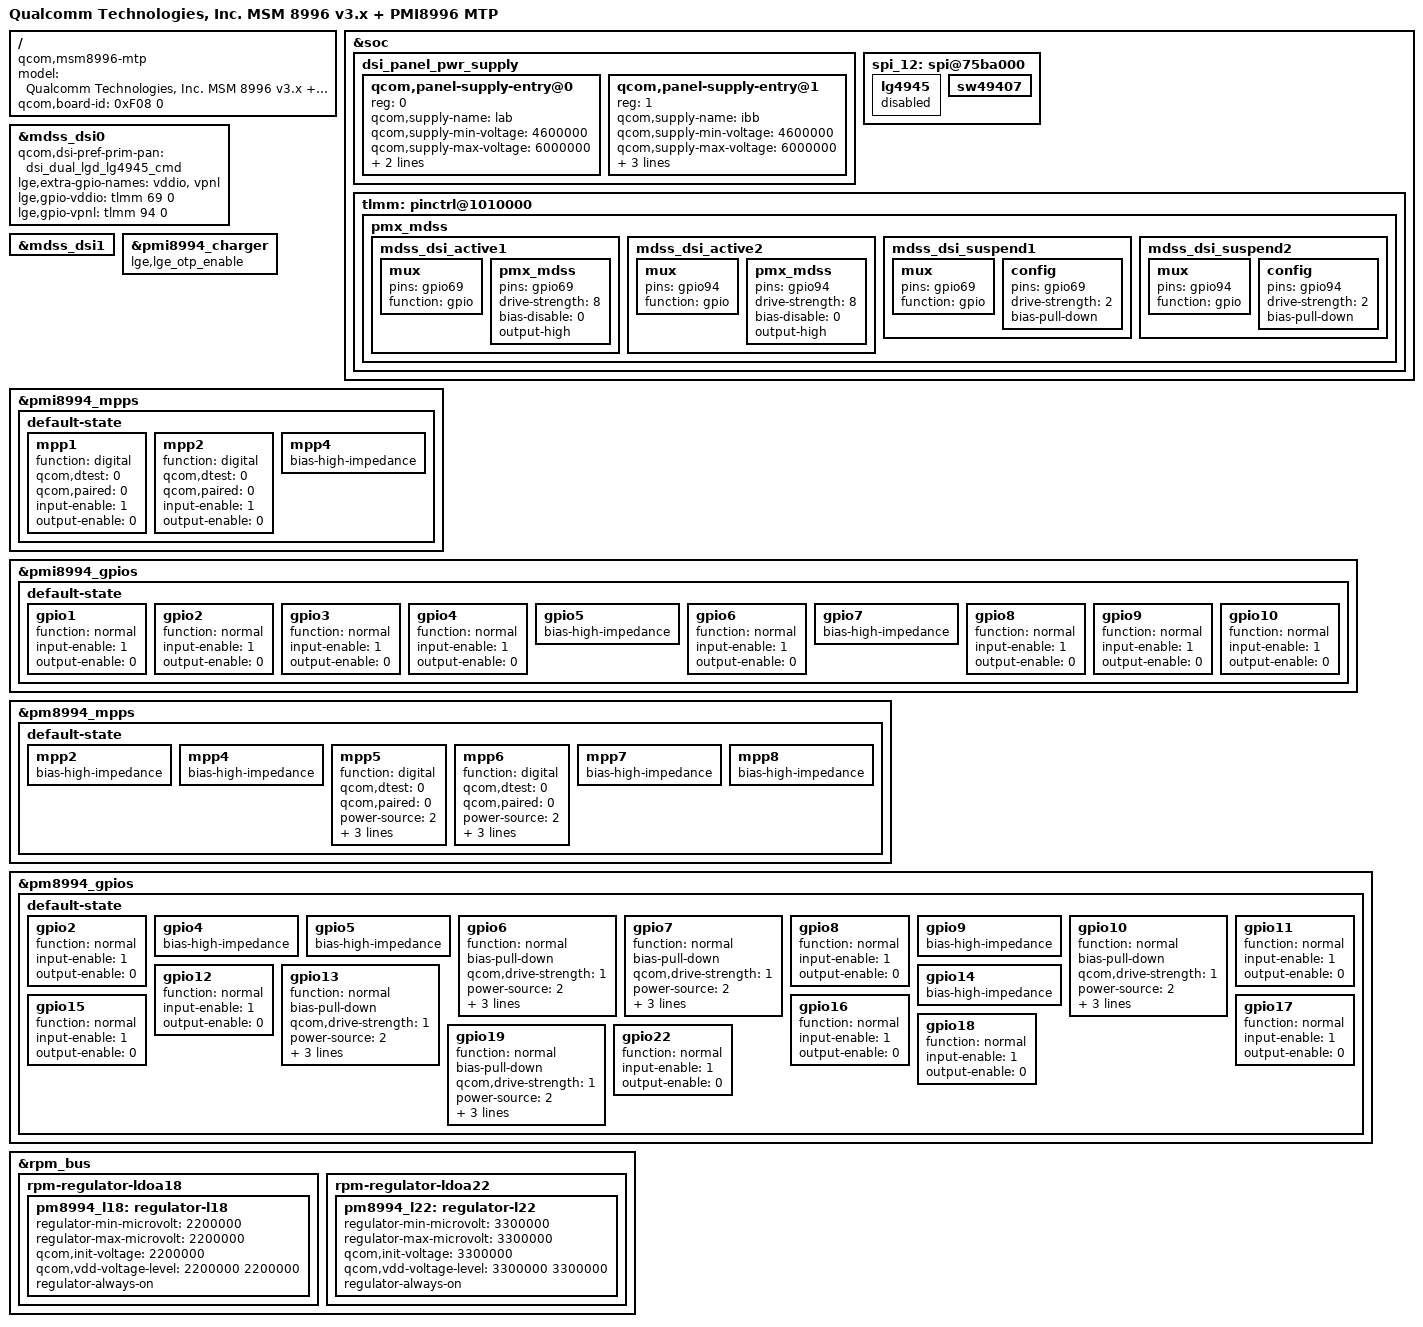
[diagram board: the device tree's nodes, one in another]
/* Copyright (c) 2015, The Linux Foundation. All rights reserved.
 *
 * This program is free software; you can redistribute it and/or modify
 * it under the terms of the GNU General Public License version 2 and
 * only version 2 as published by the Free Software Foundation.
 *
 * This program is distributed in the hope that it will be useful,
 * but WITHOUT ANY WARRANTY; without even the implied warranty of
 * MERCHANTABILITY or FITNESS FOR A PARTICULAR PURPOSE.  See the
 * GNU General Public License for more details.
 */


/dts-v1/;

#include "../../../qcom/msm8996-v3.dtsi"
#include "../../../qcom/msm-pmi8996.dtsi"
#include "../../../qcom/msm8996-mtp.dtsi"
#include "msm8996-elsa_global_com.dtsi"
#include "../common/camera/camera_rev-1.0.dtsi"
#include "../common/sound/sound_rev-1_0.dtsi"

/ {
	model = "Qualcomm Technologies, Inc. MSM 8996 v3.x + PMI8996 MTP";
	compatible = "qcom,msm8996-mtp", "qcom,msm8996", "qcom,mtp";
	qcom,board-id = <0xF08 0>;
};

/* Display Function */
&soc {
	dsi_panel_pwr_supply: dsi_panel_pwr_supply {
		#address-cells = <1>;
		#size-cells = <0>;

		qcom,panel-supply-entry@0 {
			reg = <0>;
			qcom,supply-name = "lab";
			qcom,supply-min-voltage = <4600000>;
			qcom,supply-max-voltage = <6000000>;
			qcom,supply-enable-load = <100000>;
			qcom,supply-disable-load = <100>;
		};

		qcom,panel-supply-entry@1 {
			reg = <1>;
			qcom,supply-name = "ibb";
			qcom,supply-min-voltage = <4600000>;
			qcom,supply-max-voltage = <6000000>;
			qcom,supply-enable-load = <100000>;
			qcom,supply-disable-load = <100>;
			qcom,supply-post-on-sleep = <20>;
		};
	};

	spi_12: spi@75ba000{    /* BLSP-2 QUP6 */
		lg4945 {
			status = "disabled";
		};
		sw49407 {
			status = "ok";
		};
	};
};

&mdss_dsi0 {
	qcom,dsi-pref-prim-pan = <&dsi_dual_lgd_lg4945_cmd>;
	lge,extra-gpio-names = "vddio", "vpnl";

	lge,gpio-vddio = <&tlmm 69 0>;
	lge,gpio-vpnl = <&tlmm 94 0>;
};

&mdss_dsi1 {
	/delete-property/cell-index;
};

/* pinctrl for Display function
 * GPIO69 : LCD_VDD_IO_EN
 * GPIO94 : LCD_VCL_EN
 */
&soc {
	tlmm: pinctrl@1010000 {
		pmx_mdss: pmx_mdss {
			mdss_dsi_active1: mdss_dsi_active1 {
				mux {
					pins = "gpio69";
					function = "gpio";
				};

				pmx_mdss {
					pins = "gpio69";
					drive-strength = <8>; /* 8 mA */
					bias-disable = <0>; /* no pull */
					output-high;
				};
			};
			mdss_dsi_active2: mdss_dsi_active2 {
				mux {
					pins = "gpio94";
					function = "gpio";
				};

				pmx_mdss {
					pins = "gpio94";
					drive-strength = <8>; /* 8 mA */
					bias-disable = <0>; /* no pull */
					output-high;
				};
			};
			mdss_dsi_suspend1: mdss_dsi_suspend1 {
				mux {
					pins = "gpio69";
					function = "gpio";
				};

				config {
					pins = "gpio69";
					drive-strength = <2>; /* 2 mA */
					bias-pull-down; /* pull down */
				};
			};
			mdss_dsi_suspend2: mdss_dsi_suspend2 {
				mux {
					pins = "gpio94";
					function = "gpio";
				};

				config {
					pins = "gpio94";
					drive-strength = <2>; /* 2 mA */
					bias-pull-down; /* pull down */
				};
			};
		};
	};
};

&pmi8994_charger {
    lge,lge_otp_enable;
};

/* set unused and changed assigne gpios on here */
&pmi8994_mpps {
	default-state {
/* Must not define the mpp(mpp 3) on here */
	mpp1 {
			function = "digital";
			qcom,dtest = <0>;
			qcom,paired = <0>;
			input-enable = <1>;
			output-enable = <0>;
			/delete-property/ output-low;
			/delete-property/ output-high;
			/delete-property/ bias-high-impedance;
			status = "okay";
		};

	mpp2 {
			function = "digital";
			qcom,dtest = <0>;
			qcom,paired = <0>;
			input-enable = <1>;
			output-enable = <0>;
			/delete-property/ output-low;
			/delete-property/ output-high;
			/delete-property/ bias-high-impedance;
			status = "okay";
		};

	mpp4 {
			bias-high-impedance;
			status = "okay";
		};
	};
};

&pmi8994_gpios {
	default-state {
	gpio1 {
			function = "normal";
			input-enable = <1>;
			output-enable = <0>;
			/delete-property/ output-low;
			/delete-property/ output-high;
			/delete-property/ bias-high-impedance;
			status = "okay";
		};

	gpio2 {
			function = "normal";
			input-enable = <1>;
			output-enable = <0>;
			/delete-property/ output-low;
			/delete-property/ output-high;
			/delete-property/ bias-high-impedance;
			status = "okay";
		};

	gpio3 {
			function = "normal";
			input-enable = <1>;
			output-enable = <0>;
			/delete-property/ output-low;
			/delete-property/ output-high;
			/delete-property/ bias-high-impedance;
			status = "okay";
		};

	gpio4 {
			function = "normal";
			input-enable = <1>;
			output-enable = <0>;
			/delete-property/ output-low;
			/delete-property/ output-high;
			/delete-property/ bias-high-impedance;
			status = "okay";
		};

	gpio5 {
			bias-high-impedance;
			status = "okay";
		};

	gpio6 {
			function = "normal";
			input-enable = <1>;
			output-enable = <0>;
			/delete-property/ output-low;
			/delete-property/ output-high;
			/delete-property/ bias-high-impedance;
			status = "okay";
		};

	gpio7 {
			bias-high-impedance;
			status = "okay";
		};

	gpio8 {
			function = "normal";
			input-enable = <1>;
			output-enable = <0>;
			/delete-property/ output-low;
			/delete-property/ output-high;
			/delete-property/ bias-high-impedance;
			status = "okay";
		};

	gpio9 {
			function = "normal";
			input-enable = <1>;
			output-enable = <0>;
			/delete-property/ output-low;
			/delete-property/ output-high;
			/delete-property/ bias-high-impedance;
			status = "okay";
		};

	gpio10 {
			function = "normal";
			input-enable = <1>;
			output-enable = <0>;
			/delete-property/ output-low;
			/delete-property/ output-high;
			/delete-property/ bias-high-impedance;
			status = "okay";
		};
	};
};

&pm8994_mpps {
	default-state {
/* Must not define the mpps(mpp 1 and 3) on here */
	mpp2 {
			bias-high-impedance;
			status = "okay";
		};

	mpp4 {
			bias-high-impedance;
			status = "okay";
		};

	mpp5 {
			function = "digital";
			qcom,dtest = <0>;
			qcom,paired = <0>;
			power-source = <2>;
			input-enable = <0>;
			output-enable = <1>;
			/delete-property/ output-low;
			/delete-property/ output-high;
			output-low;
			/delete-property/ bias-high-impedance;
			status = "okay";
		};

	mpp6 {
			function = "digital";
			qcom,dtest = <0>;
			qcom,paired = <0>;
			power-source = <2>;
			input-enable = <0>;
			output-enable = <1>;
			/delete-property/ output-low;
			/delete-property/ output-high;
			output-low;
			/delete-property/ bias-high-impedance;
			status = "okay";
		};

	mpp7 {
			bias-high-impedance;
			status = "okay";
		};

	mpp8 {
			bias-high-impedance;
			status = "okay";
		};
	};
};

&pm8994_gpios {
	default-state {
/* Gpio 1 and 3 is set on relevant usb-type-c */
/* at "kernel\arch\arm64\boot\dts\lge\msm8996-usb-typec-anx7418.dtsi" */
/* Must not define the gpios(gpio 20 and 21) on here */
	gpio2 {
			function = "normal";
			input-enable = <1>;
			output-enable = <0>;
			/delete-property/ output-low;
			/delete-property/ output-high;
			/delete-property/ bias-high-impedance;
			status = "okay";
		};

	gpio4 {
			bias-high-impedance;
			status = "okay";
		};

	gpio5 {
			bias-high-impedance;
			status = "okay";
		};

	gpio6 {
			function = "normal";
			/delete-property/ bias-disable;
			/delete-property/ bias-pull-down;
			/delete-property/ qcom,pull-up-strength;
			bias-pull-down;
			qcom,drive-strength = <1>;
			power-source = <2>;
			input-enable = <0>;
			output-enable = <1>;
			/delete-property/ output-low;
			/delete-property/ output-high;
			output-low;
			/delete-property/ bias-high-impedance;
			status = "okay";
		};

	gpio7 {
			function = "normal";
			/delete-property/ bias-disable;
			/delete-property/ bias-pull-down;
			/delete-property/ qcom,pull-up-strength;
			bias-pull-down;
			qcom,drive-strength = <1>;
			power-source = <2>;
			input-enable = <0>;
			output-enable = <1>;
			/delete-property/ output-low;
			/delete-property/ output-high;
			output-low;
			/delete-property/ bias-high-impedance;
			status = "okay";
		};

	gpio8 {
			function = "normal";
			input-enable = <1>;
			output-enable = <0>;
			/delete-property/ output-low;
			/delete-property/ output-high;
			/delete-property/ bias-high-impedance;
			status = "okay";
		};

	gpio9 {
			bias-high-impedance;
			status = "okay";
		};

	gpio10 {
			function = "normal";
			/delete-property/ bias-disable;
			/delete-property/ bias-pull-down;
			/delete-property/ qcom,pull-up-strength;
			bias-pull-down;
			qcom,drive-strength = <1>;
			power-source = <2>;
			input-enable = <0>;
			output-enable = <1>;
			/delete-property/ output-low;
			/delete-property/ output-high;
			output-low;
			/delete-property/ bias-high-impedance;
			status = "okay";
		};

	gpio11 {
			function = "normal";
			input-enable = <1>;
			output-enable = <0>;
			/delete-property/ output-low;
			/delete-property/ output-high;
			/delete-property/ bias-high-impedance;
			status = "okay";
		};

	gpio12 {
			function = "normal";
			input-enable = <1>;
			output-enable = <0>;
			/delete-property/ output-low;
			/delete-property/ output-high;
			/delete-property/ bias-high-impedance;
			status = "okay";
		};

	gpio13 {
			function = "normal";
			/delete-property/ bias-disable;
			/delete-property/ bias-pull-down;
			/delete-property/ qcom,pull-up-strength;
			bias-pull-down;
			qcom,drive-strength = <1>;
			power-source = <2>;
			input-enable = <0>;
			output-enable = <1>;
			/delete-property/ output-low;
			/delete-property/ output-high;
			output-low;
			/delete-property/ bias-high-impedance;
			status = "okay";
		};

	gpio14 {
			bias-high-impedance;
			status = "okay";
		};

	gpio15 {
			function = "normal";
			input-enable = <1>;
			output-enable = <0>;
			/delete-property/ output-low;
			/delete-property/ output-high;
			/delete-property/ bias-high-impedance;
			status = "okay";
		};

	gpio16 {
			function = "normal";
			input-enable = <1>;
			output-enable = <0>;
			/delete-property/ output-low;
			/delete-property/ output-high;
			/delete-property/ bias-high-impedance;
			status = "okay";
		};

	gpio17 {
			function = "normal";
			input-enable = <1>;
			output-enable = <0>;
			/delete-property/ output-low;
			/delete-property/ output-high;
			/delete-property/ bias-high-impedance;
			status = "okay";
		};

	gpio18 {
			function = "normal";
			input-enable = <1>;
			output-enable = <0>;
			/delete-property/ output-low;
			/delete-property/ output-high;
			/delete-property/ bias-high-impedance;
			status = "okay";
		};

	gpio19 {
			function = "normal";
			/delete-property/ bias-disable;
			/delete-property/ bias-pull-down;
			/delete-property/ qcom,pull-up-strength;
			bias-pull-down;
			qcom,drive-strength = <1>;
			power-source = <2>;
			input-enable = <0>;
			output-enable = <1>;
			/delete-property/ output-low;
			/delete-property/ output-high;
			output-low;
			/delete-property/ bias-high-impedance;
			status = "okay";
		};
	gpio22 {
			function = "normal";
			input-enable = <1>;
			output-enable = <0>;
			/delete-property/ output-low;
			/delete-property/ output-high;
			/delete-property/ bias-high-impedance;
			status = "okay";
		};
	};
};

&rpm_bus {
	rpm-regulator-ldoa18 {
		status = "okay";
		pm8994_l18: regulator-l18 {
			regulator-min-microvolt = <2200000>;
			regulator-max-microvolt = <2200000>;
			qcom,init-voltage       = <2200000>;
			qcom,vdd-voltage-level = <2200000 2200000>;
			regulator-always-on;
			status = "okay";
		};
	};
	rpm-regulator-ldoa22 { /* regulator LDO22 - For Headset Detect */
		status = "okay";
		pm8994_l22: regulator-l22 {
			regulator-min-microvolt = <3300000>;
			regulator-max-microvolt = <3300000>;
			qcom,init-voltage       = <3300000>;
			qcom,vdd-voltage-level = <3300000 3300000>;
			regulator-always-on;
			status = "okay";
		};
	};
};
